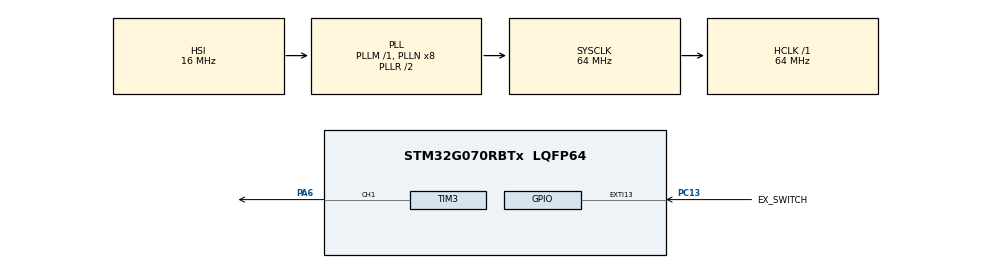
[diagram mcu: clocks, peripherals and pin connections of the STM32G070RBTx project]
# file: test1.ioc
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Mcu.Family=STM32G0
Mcu.Name=STM32G070RBTx
Mcu.Package=LQFP64
NVIC.EXTI4_15_IRQn=true\:0\:0\:false\:false\:true\:true\:true\:true
NVIC.TIM3_IRQn=true\:0\:0\:false\:false\:true\:true\:true\:true
PA6.GPIO_PuPd=GPIO_PULLUP
PA6.Signal=S_TIM3_CH1
PC13.GPIO_Label=EX_SWITCH
PC13.GPIO_ModeDefaultEXTI=GPIO_MODE_IT_FALLING
PC13.GPIO_PuPd=GPIO_PULLDOWN
PC13.Signal=GPXTI13
PC14-OSC32_IN\ (PC14).Mode=LSE-External-Oscillator
PC14-OSC32_IN\ (PC14).Signal=RCC_OSC32_IN
PC15-OSC32_OUT\ (PC15).Mode=LSE-External-Oscillator
PC15-OSC32_OUT\ (PC15).Signal=RCC_OSC32_OUT
PF0-OSC_IN\ (PF0).GPIO_Label=MCO
PF0-OSC_IN\ (PF0).Mode=HSE-External-Clock-Source
PF0-OSC_IN\ (PF0).Signal=RCC_OSC_IN
ProjectManager.HeapSize=0x200
ProjectManager.StackSize=0x400
ProjectManager.TargetToolchain=STM32CubeIDE
RCC.ADCFreq_Value=64000000
RCC.AHBFreq_Value=64000000
RCC.APB1CLKDivider=RCC_HCLK_DIV16
RCC.CortexFreq_Value=64000000
RCC.EXTERNAL_CLOCK_VALUE=12288000
RCC.HCLKFreq_Value=64000000
RCC.HSE_VALUE=8000000
RCC.HSI_VALUE=16000000
RCC.SYSCLKFreq_VALUE=64000000
RCC.SYSCLKSource=RCC_SYSCLKSOURCE_PLLCLK
RCC.VCOOutputFreq_Value=128000000
SH.S_TIM3_CH1.0=TIM3_CH1,PWM Generation1 CH1
TIM3.Channel-PWM\ Generation1\ CH1=TIM_CHANNEL_1
TIM3.Period=0
TIM3.Prescaler=8000-1
VP_TIM3_VS_ClockSourceINT.Mode=Internal
board=NUCLEO-G070RB

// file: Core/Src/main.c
/* USER CODE BEGIN Header */
/**
  ******************************************************************************
  * @file           : main.c
  * @brief          : Main program body
  ******************************************************************************
  * @attention
  *
  * Copyright (c) 2025 STMicroelectronics.
  * All rights reserved.
  *
  * This software is licensed under terms that can be found in the LICENSE file
  * in the root directory of this software component.
  * If no LICENSE file comes with this software, it is provided AS-IS.
  *
  ******************************************************************************
  */
/* USER CODE END Header */
#include "main.h"

/* USER CODE BEGIN PD */
#define LED_PIN GPIO_PIN_6
#define LED_GPIO_PORT GPIOA
#define SWITCH_PIN GPIO_PIN_13
#define SWITCH_GPIO_PORT GPIOC
/* USER CODE END PD */

TIM_HandleTypeDef htim3;

/* USER CODE BEGIN PV */
uint32_t tick = 0 ;
uint32_t previousTick = 0 ;
volatile uint8_t switch_press_count = 0;
volatile uint8_t led_state = 0;
volatile uint32_t blink_frequency = 0;
/* USER CODE END PV */

void SystemClock_Config(void);
static void MX_GPIO_Init(void);
static void MX_TIM3_Init(void);

/* USER CODE BEGIN 0 */
__weak void HAL_GPIO_EXTI_IRQHandler(uint16_t GPIO_PIN){
	if (HAL_GPIO_ReadPin(SWITCH_GPIO_PORT, SWITCH_PIN) == GPIO_PIN_SET) {
		  	 		           // Debounce delay
		  	 			        tick++;
		  	 			        if( (tick - previousTick) > 5 ){
		  	 		           while (HAL_GPIO_ReadPin(SWITCH_GPIO_PORT, SWITCH_PIN) == GPIO_PIN_SET){
		  	 		           // Increment switch press count
		  	 		           switch_press_count = (switch_press_count %4)+1;
		  	 		           //switch_press_count++;
		  	 		           // Reset count after 4 presses
		  	 		           if (switch_press_count > 4) {
		  	 		               switch_press_count = 1;
		  	 		           }
		  	 			        }
}
	}
}
/* USER CODE END 0 */

int main(void)
{

  /* MCU Configuration--------------------------------------------------------*/

  /* Reset of all peripherals, Initializes the Flash interface and the Systick. */
  HAL_Init();

  /* Configure the system clock */
  SystemClock_Config();

  /* Initialize all configured peripherals */
  MX_GPIO_Init();
  MX_TIM3_Init();

  /* Infinite loop */
  while (1)
  {

    /* USER CODE BEGIN 3 */
	  switch (switch_press_count) {
	                case 1:
	                    blink_frequency = 2000; // 0.5 Hz (1000 ms on, 1000 ms off)
	                    break;
	                case 2:
	                    blink_frequency = 1000;  // 1 Hz (500 ms on, 500 ms off)
	                    break;
	                case 3:
	                    blink_frequency = 500;  // 2 Hz (250 ms on, 250 ms off)
	                    break;
	                case 4:
	                    blink_frequency = 0;    // Turn off LED
	                    HAL_GPIO_WritePin(LED_GPIO_PORT, LED_PIN, GPIO_PIN_RESET);
	                    Enter_LowPowerMode();
	                    break;
	            }

	            // Update timer period if LED is blinking
	            if (blink_frequency > 0) {
	                TIM3->ARR = blink_frequency-1;
	                HAL_TIM_Base_Start_IT(&htim3);
	            } else {
	                HAL_TIM_Base_Stop_IT(&htim3);

	            }
  }
  /* USER CODE END 3 */
}

void SystemClock_Config(void)
{
  RCC_OscInitTypeDef RCC_OscInitStruct = {0};
  RCC_ClkInitTypeDef RCC_ClkInitStruct = {0};

  /** Configure the main internal regulator output voltage
  */
  HAL_PWREx_ControlVoltageScaling(PWR_REGULATOR_VOLTAGE_SCALE1);

  /** Initializes the RCC Oscillators according to the specified parameters
  * in the RCC_OscInitTypeDef structure.
  */
  RCC_OscInitStruct.OscillatorType = RCC_OSCILLATORTYPE_HSI;
  RCC_OscInitStruct.HSIState = RCC_HSI_ON;
  RCC_OscInitStruct.HSIDiv = RCC_HSI_DIV1;
  RCC_OscInitStruct.HSICalibrationValue = RCC_HSICALIBRATION_DEFAULT;
  RCC_OscInitStruct.PLL.PLLState = RCC_PLL_ON;
  RCC_OscInitStruct.PLL.PLLSource = RCC_PLLSOURCE_HSI;
  RCC_OscInitStruct.PLL.PLLM = RCC_PLLM_DIV1;
  RCC_OscInitStruct.PLL.PLLN = 8;
  RCC_OscInitStruct.PLL.PLLP = RCC_PLLP_DIV2;
  RCC_OscInitStruct.PLL.PLLR = RCC_PLLR_DIV2;
  if (HAL_RCC_OscConfig(&RCC_OscInitStruct) != HAL_OK)
  {
    Error_Handler();
  }

  /** Initializes the CPU, AHB and APB buses clocks
  */
  RCC_ClkInitStruct.ClockType = RCC_CLOCKTYPE_HCLK|RCC_CLOCKTYPE_SYSCLK
                              |RCC_CLOCKTYPE_PCLK1;
  RCC_ClkInitStruct.SYSCLKSource = RCC_SYSCLKSOURCE_PLLCLK;
  RCC_ClkInitStruct.AHBCLKDivider = RCC_SYSCLK_DIV1;
  RCC_ClkInitStruct.APB1CLKDivider = RCC_HCLK_DIV16;

  if (HAL_RCC_ClockConfig(&RCC_ClkInitStruct, FLASH_LATENCY_2) != HAL_OK)
  {
    Error_Handler();
  }
}

static void MX_TIM3_Init(void)
{

  TIM_ClockConfigTypeDef sClockSourceConfig = {0};
  TIM_MasterConfigTypeDef sMasterConfig = {0};
  TIM_OC_InitTypeDef sConfigOC = {0};

  htim3.Instance = TIM3;
  htim3.Init.Prescaler = 8000-1;
  htim3.Init.CounterMode = TIM_COUNTERMODE_UP;
  htim3.Init.Period = 0;
  htim3.Init.ClockDivision = TIM_CLOCKDIVISION_DIV1;
  htim3.Init.AutoReloadPreload = TIM_AUTORELOAD_PRELOAD_DISABLE;
  if (HAL_TIM_Base_Init(&htim3) != HAL_OK)
  {
    Error_Handler();
  }
  sClockSourceConfig.ClockSource = TIM_CLOCKSOURCE_INTERNAL;
  if (HAL_TIM_ConfigClockSource(&htim3, &sClockSourceConfig) != HAL_OK)
  {
    Error_Handler();
  }
  if (HAL_TIM_PWM_Init(&htim3) != HAL_OK)
  {
    Error_Handler();
  }
  sMasterConfig.MasterOutputTrigger = TIM_TRGO_RESET;
  sMasterConfig.MasterSlaveMode = TIM_MASTERSLAVEMODE_DISABLE;
  if (HAL_TIMEx_MasterConfigSynchronization(&htim3, &sMasterConfig) != HAL_OK)
  {
    Error_Handler();
  }
  sConfigOC.OCMode = TIM_OCMODE_PWM1;
  sConfigOC.Pulse = 0;
  sConfigOC.OCPolarity = TIM_OCPOLARITY_HIGH;
  sConfigOC.OCFastMode = TIM_OCFAST_DISABLE;
  if (HAL_TIM_PWM_ConfigChannel(&htim3, &sConfigOC, TIM_CHANNEL_1) != HAL_OK)
  {
    Error_Handler();
  }
  HAL_TIM_MspPostInit(&htim3);

}

static void MX_GPIO_Init(void)
{
  GPIO_InitTypeDef GPIO_InitStruct = {0};

  /* GPIO Ports Clock Enable */
  __HAL_RCC_GPIOC_CLK_ENABLE();
  __HAL_RCC_GPIOF_CLK_ENABLE();
  __HAL_RCC_GPIOA_CLK_ENABLE();

  /*Configure GPIO pin : EX_SWITCH_Pin */
  GPIO_InitStruct.Pin = EX_SWITCH_Pin;
  GPIO_InitStruct.Mode = GPIO_MODE_IT_FALLING;
  GPIO_InitStruct.Pull = GPIO_PULLDOWN;
  HAL_GPIO_Init(EX_SWITCH_GPIO_Port, &GPIO_InitStruct);

  /* EXTI interrupt init*/
  HAL_NVIC_SetPriority(EXTI4_15_IRQn, 0, 0);
  HAL_NVIC_EnableIRQ(EXTI4_15_IRQn);

}

/* USER CODE BEGIN 4 */
void Enter_LowPowerMode(void) {
    // Configure GPIOs for low power
    HAL_GPIO_DeInit(LED_GPIO_PORT, LED_PIN);
    HAL_GPIO_DeInit(SWITCH_GPIO_PORT, SWITCH_PIN);

    // Enter STOP mode
    HAL_PWR_EnterSTOPMode(PWR_LOWPOWERREGULATOR_ON, PWR_STOPENTRY_WFI);

    // Re-configure GPIOs after waking up
    MX_GPIO_Init();
    SystemClock_Config(); // Re-initialize clock after wakeup
     HAL_ResumeTick();
}

/* USER CODE END 4 */

void Error_Handler(void)
{
  __disable_irq();
  while (1)
  {
  }
}
